AUTOSAR XML (schema 4-0-3)
package /ComponentTypes
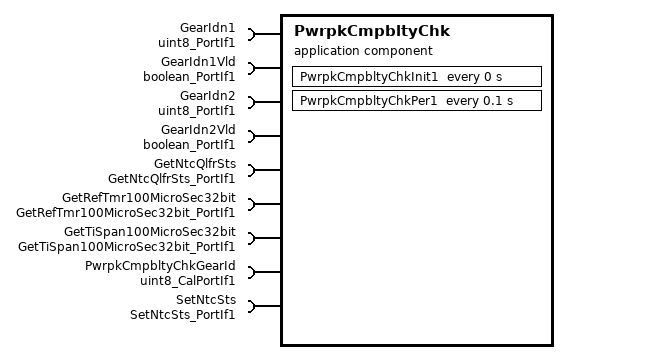
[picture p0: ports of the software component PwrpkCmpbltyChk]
  application sw component type PwrpkCmpbltyChk
    9 x require port:
      GearIdn1: nonqueued-receiver-com-spec{data-element=Val, filter=data-filter-type=ALWAYS, init-value=0}, required-interface=uint8_PortIf1
      GearIdn1Vld: nonqueued-receiver-com-spec{data-element=Logl, filter=data-filter-type=ALWAYS, init-value=0}, required-interface=boolean_PortIf1
      GearIdn2: nonqueued-receiver-com-spec{data-element=Val, filter=data-filter-type=ALWAYS, init-value=0}, required-interface=uint8_PortIf1
      GearIdn2Vld: nonqueued-receiver-com-spec{data-element=Logl, filter=data-filter-type=ALWAYS, init-value=0}, required-interface=boolean_PortIf1
      GetNtcQlfrSts: required-interface=GetNtcQlfrSts_PortIf1
      GetRefTmr100MicroSec32bit: required-interface=GetRefTmr100MicroSec32bit_PortIf1
      GetTiSpan100MicroSec32bit: required-interface=GetTiSpan100MicroSec32bit_PortIf1
      PwrpkCmpbltyChkGearId: parameter-require-com-spec{init-value=0, parameter=Val}, required-interface=uint8_CalPortIf1
      SetNtcSts: required-interface=SetNtcSts_PortIf1
    behavior PwrpkCmpbltyChk_InternalBehavior
      ar-typed-per-instance-memorys:
        data GearIdnRefTmr: sw-calibration-access=READ-ONLY, type=uint32
      timing event PwrpkCmpbltyChkInit1_InitEvent: start-on-event=PwrpkCmpbltyChkInit1, period=0
      timing event TMT_PwrpkCmpbltyChkPer1: start-on-event=PwrpkCmpbltyChkPer1, period=0.1
      runnable PwrpkCmpbltyChkInit1
        sync call SC_GetRefTmr100MicroSec32bit_Oper: operation=GetRefTmr100MicroSec32bit.Oper, timeout=0
      runnable PwrpkCmpbltyChkPer1
        data-receive-point-by-arguments:
          4 x access:
            REC_GearIdn1_Val: accessed-variable=GearIdn1.Val
            REC_GearIdn1Vld_Logl: accessed-variable=GearIdn1Vld.Logl
            REC_GearIdn22_Val: accessed-variable=GearIdn2.Val
            REC_GearIdn2Vld_Logl: accessed-variable=GearIdn2Vld.Logl
        sync call SC_GetNtcQlfrSts_Oper: operation=GetNtcQlfrSts.Oper, timeout=0
        sync call SC_GetTiSpan100MicroSec32bit_Oper: operation=GetTiSpan100MicroSec32bit.Oper, timeout=0
        sync call SC_SetNtcSts_Oper: operation=SetNtcSts.Oper, timeout=0
  swc implementation PwrpkCmpbltyChk_Implementation: behavior=PwrpkCmpbltyChk_InternalBehavior
    code-descriptors:
      code Default: artifact-descriptors=autosar-engineering-object={short-label=Default, category=SWSRC}
